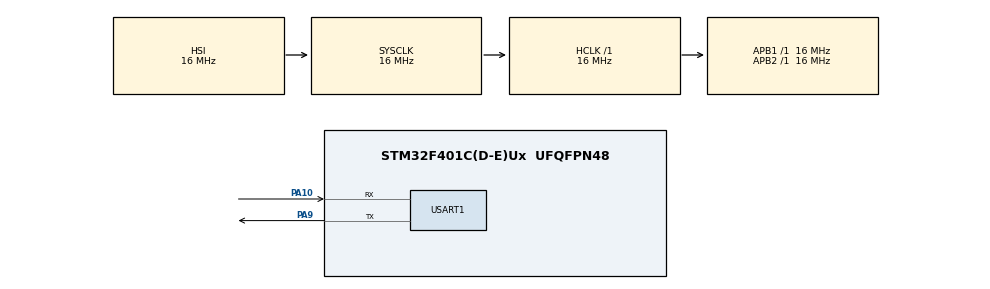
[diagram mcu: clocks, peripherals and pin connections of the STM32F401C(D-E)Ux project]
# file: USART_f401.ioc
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Mcu.Family=STM32F4
Mcu.Name=STM32F401C(D-E)Ux
Mcu.Package=UFQFPN48
NVIC.PriorityGroup=NVIC_PRIORITYGROUP_4
NVIC.USART1_IRQn=true\:0\:0\:false\:false\:true\:true\:true\:true
PA10.Mode=Asynchronous
PA10.Signal=USART1_RX
PA9.Mode=Asynchronous
PA9.Signal=USART1_TX
ProjectManager.HeapSize=0x200
ProjectManager.StackSize=0x400
ProjectManager.TargetToolchain=STM32CubeIDE
RCC.AHBFreq_Value=16000000
RCC.APB1Freq_Value=16000000
RCC.APB2Freq_Value=16000000
RCC.CortexFreq_Value=16000000
RCC.HSE_VALUE=25000000
RCC.HSI_VALUE=16000000
RCC.LSE_VALUE=32768
RCC.SYSCLKFreq_VALUE=16000000
RCC.VCOOutputFreq_Value=192000000
USART1.VirtualMode=VM_ASYNC
board=custom

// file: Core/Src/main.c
/* USER CODE BEGIN Header */
/**
  ******************************************************************************
  * @file           : main.c
  * @brief          : Main program body
  ******************************************************************************
  * @attention
  *
  * Copyright (c) 2024 STMicroelectronics.
  * All rights reserved.
  *
  * This software is licensed under terms that can be found in the LICENSE file
  * in the root directory of this software component.
  * If no LICENSE file comes with this software, it is provided AS-IS.
  *
  ******************************************************************************
  */

/* USER CODE END Header */
#include "main.h"
/* USER CODE BEGIN Includes */
#include <stdio.h>
#include <string.h>
#include "at_comand.h"
#include "at_flash.h"
/* USER CODE END Includes */

UART_HandleTypeDef huart1;

/* USER CODE BEGIN PV */
struct my_struct par;
type (*pointer)(void);
//void (*pointer)(void);

/* USER CODE END PV */

void SystemClock_Config(void);
static void MX_GPIO_Init(void);
static void MX_USART1_UART_Init(void);

int main(void)
{

  /* MCU Configuration--------------------------------------------------------*/

  /* Reset of all peripherals, Initializes the Flash interface and the Systick. */
  HAL_Init();

  /* Configure the system clock */
  SystemClock_Config();

  /* Initialize all configured peripherals */
  MX_GPIO_Init();
  MX_USART1_UART_Init();
  /* USER CODE BEGIN 2 */
  HAL_NVIC_SetPriority(USART1_IRQn, 0, 0);
  HAL_NVIC_EnableIRQ(USART1_IRQn);
  par.num0=1;//№ параметра
  par.num1=2;
  par.num2=3;
  par.num3=4;
  par.num4=5;
  par.num5=6;
  par.num6=7;
  par.num7=8;
  par.num8=9;
  par.num9=10;
  par.num10=11;
  par.num11=12;
  /* USER CODE END 2 */

  /* Infinite loop */
  /* USER CODE BEGIN WHILE */
  HAL_UART_Receive_IT(&huart1, &rxbyte, 1);//вызов приёма, подготовка к приёму
  while (1)
  {
    /* USER CODE END WHILE */
	  if (flag==1)
	  {
		  pointer=adr_func[check()];//pointer указатель на функцию, adr_func массив адресов функций
		  pointer();
		  /*switch (check())
	      {
	      	  case 0:
	      		  //sprintf(writeBuf, "%s", readBuf);//передаём в массив writeBuf
	      		  SPD();//скорость соединения
	      		  break;
	          case 1:
	               //sprintf(writeBuf, "%s", readBuf);//передаём в массив writeBuf
	               LNOPEN();//расстояние полного открытия
	               break;
	          case 2:
	               //sprintf(writeBuf, "%s", readBuf);//передаём в массив writeBuf
	               LNHLOPEN();//расстояние неполного открытия
	               break;
	          case 3:
	               //sprintf(writeBuf, "%s", readBuf);//передаём в массив writeBuf
	               CURERRLOCK1();//аварийное значение токо линии замков 1
	               break;
	          case 4:
	               //sprintf(writeBuf, "%s", readBuf);//передаём в массив writeBuf
	               CURERRLOCK2();//аварийное значение токо линии замков 2
	               break;
	          case 5:
	               //sprintf(writeBuf, "%s", readBuf);//передаём в массив writeBuf
	               CURERRDRIVE1();//аварийное значение  тока линии цепей привода окна 1
	               break;
	          case 6:
	               //sprintf(writeBuf, "%s", readBuf);//передаём в массив writeBuf
	               CURERRDRIVE2();//аварийное значение  тока линии цепей привода окна 2
	               break;
	          case 7:
	               //sprintf(writeBuf, "%s", readBuf);//передаём в массив writeBuf
	               CURERRDRIVE3();//аварийное значение  тока линии цепей привода окна 3
	               break;
	          case 8:
	               //sprintf(writeBuf, "%s", readBuf);//передаём в массив writeBuf
	               CURERRDRIVE4();//аварийное значение  тока линии цепей привода окна 4
	               break;
	          case 9:
	               //sprintf(writeBuf, "%s", readBuf);//передаём в массив writeBuf
	               CURERRTIME();//время удержания аварийного значения  тока линии цепей
	               break;
	          case 10:
	               //sprintf(writeBuf, "%s", readBuf);//передаём в массив writeBuf
	               STOTIMELOCK();//время нахождения в упоре замков
	               break;
	          case 11:
	        	  //sprintf(writeBuf, "%s", readBuf);//передаём в массив writeBuf
	              STOTIMEDRIVE();//время нахождения в упоре цепей
	              break;
	          case 12:
	        	  //sprintf(writeBuf, "%s", readBuf);//передаём в массив writeBuf
	              SAVEFLASH();//сохранить всё во flash
	              break;
	          case 13:
	        	  //sprintf(writeBuf, "%s", readBuf);//передаём в массив writeBuf
	              READFLASH();//"холодный старт"
	              break;
	          default:
	              sprintf(writeBuf, "%s", "Error\r\n");//передаём в массив writeBuf
	              break;
	      }*/
	           	 flag=0;//сбрасываем флаг
	             HAL_UART_Transmit(&huart1, (uint8_t*)writeBuf, strlen(writeBuf), HAL_MAX_DELAY);
	             HAL_UART_Receive_IT(&huart1, &rxbyte, 1);//вызов приёма, подготовка к приёму
	  }
  }
}

void SystemClock_Config(void)
{
  RCC_OscInitTypeDef RCC_OscInitStruct = {0};
  RCC_ClkInitTypeDef RCC_ClkInitStruct = {0};

  /** Configure the main internal regulator output voltage
  */
  __HAL_RCC_PWR_CLK_ENABLE();
  __HAL_PWR_VOLTAGESCALING_CONFIG(PWR_REGULATOR_VOLTAGE_SCALE2);

  /** Initializes the RCC Oscillators according to the specified parameters
  * in the RCC_OscInitTypeDef structure.
  */
  RCC_OscInitStruct.OscillatorType = RCC_OSCILLATORTYPE_HSI;
  RCC_OscInitStruct.HSIState = RCC_HSI_ON;
  RCC_OscInitStruct.HSICalibrationValue = RCC_HSICALIBRATION_DEFAULT;
  RCC_OscInitStruct.PLL.PLLState = RCC_PLL_NONE;
  if (HAL_RCC_OscConfig(&RCC_OscInitStruct) != HAL_OK)
  {
    Error_Handler();
  }

  /** Initializes the CPU, AHB and APB buses clocks
  */
  RCC_ClkInitStruct.ClockType = RCC_CLOCKTYPE_HCLK|RCC_CLOCKTYPE_SYSCLK
                              |RCC_CLOCKTYPE_PCLK1|RCC_CLOCKTYPE_PCLK2;
  RCC_ClkInitStruct.SYSCLKSource = RCC_SYSCLKSOURCE_HSI;
  RCC_ClkInitStruct.AHBCLKDivider = RCC_SYSCLK_DIV1;
  RCC_ClkInitStruct.APB1CLKDivider = RCC_HCLK_DIV1;
  RCC_ClkInitStruct.APB2CLKDivider = RCC_HCLK_DIV1;

  if (HAL_RCC_ClockConfig(&RCC_ClkInitStruct, FLASH_LATENCY_0) != HAL_OK)
  {
    Error_Handler();
  }
}

static void MX_USART1_UART_Init(void)
{

  huart1.Instance = USART1;
  huart1.Init.BaudRate = 115200;
  huart1.Init.WordLength = UART_WORDLENGTH_8B;
  huart1.Init.StopBits = UART_STOPBITS_1;
  huart1.Init.Parity = UART_PARITY_NONE;
  huart1.Init.Mode = UART_MODE_TX_RX;
  huart1.Init.HwFlowCtl = UART_HWCONTROL_NONE;
  huart1.Init.OverSampling = UART_OVERSAMPLING_16;
  if (HAL_UART_Init(&huart1) != HAL_OK)
  {
    Error_Handler();
  }

}

static void MX_GPIO_Init(void)
{

  /* GPIO Ports Clock Enable */
  __HAL_RCC_GPIOA_CLK_ENABLE();

}

/* USER CODE BEGIN 4 */
void HAL_UART_RxCpltCallback(UART_HandleTypeDef *UartHandle)
{
  /* Установить флаг передачи: передача завершена */
     // UartReady = SET;
      readBuf[i++]=rxbyte;//принимаем побайтно
      if (i >= sizeof(readBuf)) //если буфер переполнился
          i=0;//сбрасываем счётчик
      if (rxbyte=='\n') //если принятый байт символ перевода каретки
      {
          readBuf[i++] = '\0';//добавляем символ конца строки
          flag = 1; //устанавливаем флаг
          i=0;//сбрасываем счётчик
          //HAL_UART_AbortReceive(&huart1);//прекращение приёма из UART
      }
      else
          HAL_UART_Receive_IT(&huart1, &rxbyte, 1);//вызов приёма, подготовка к приёму
}
/* USER CODE END 4 */

void Error_Handler(void)
{
  __disable_irq();
  while (1)
  {
  }
}
